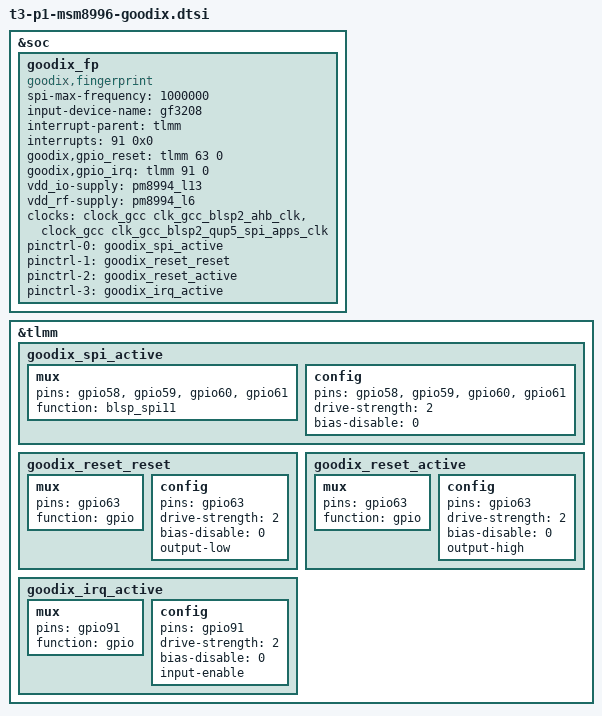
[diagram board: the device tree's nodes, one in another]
&soc {
	goodix_fp {
	compatible = "goodix,fingerprint";
	spi-max-frequency = <1000000>;
	input-device-name = "gf3208";
	interrupt-parent = <&tlmm>;
	interrupts = <91 0x0>;

	goodix,gpio_reset    = <&tlmm 63 0>;
	goodix,gpio_irq      = <&tlmm 91 0>;

	vdd_io-supply   = <&pm8994_l13>;
	vdd_rf-supply   = <&pm8994_l6>;

	clock-names = "iface_clk", "core_clk";
	clocks = <&clock_gcc clk_gcc_blsp2_ahb_clk>,
	<&clock_gcc clk_gcc_blsp2_qup5_spi_apps_clk>;

	pinctrl-names = "goodixfp_spi_active",
			"goodixfp_reset_reset",
			"goodixfp_reset_active",
			"goodixfp_irq_active";

	pinctrl-0 = <&goodix_spi_active>;
	pinctrl-1 = <&goodix_reset_reset>;
	pinctrl-2 = <&goodix_reset_active>;
	pinctrl-3 = <&goodix_irq_active>;
	};
};

&tlmm {
	goodix_spi_active: goodix_spi_active{
		mux {
			pins = "gpio58", "gpio59", "gpio60", "gpio61";
			function = "blsp_spi11";
		};
		config {
			pins = "gpio58", "gpio59", "gpio60", "gpio61";
			drive-strength = <2>;
			bias-disable = <0>;
		};
	};
	goodix_reset_reset: goodix_reset_reset{
		mux {
			pins = "gpio63";
			function = "gpio";
		};
		config {
			pins = "gpio63";
			drive-strength = <2>;
			bias-disable = <0>;
			output-low;
		};
	};
	goodix_reset_active: goodix_reset_active{
		mux {
			pins = "gpio63";
			function = "gpio";
		};
		config {
			pins = "gpio63";
			drive-strength = <2>;
			bias-disable = <0>;
			output-high;
		};
	};

	goodix_irq_active: goodix_irq_active {
		mux {
			pins = "gpio91";
			function = "gpio";
		};
		config {
			pins = "gpio91";
			drive-strength = <2>;
			bias-disable = <0>;
			input-enable;
		};
	};
};
